VERSION ""

NS_ :

BS_:

BU_:

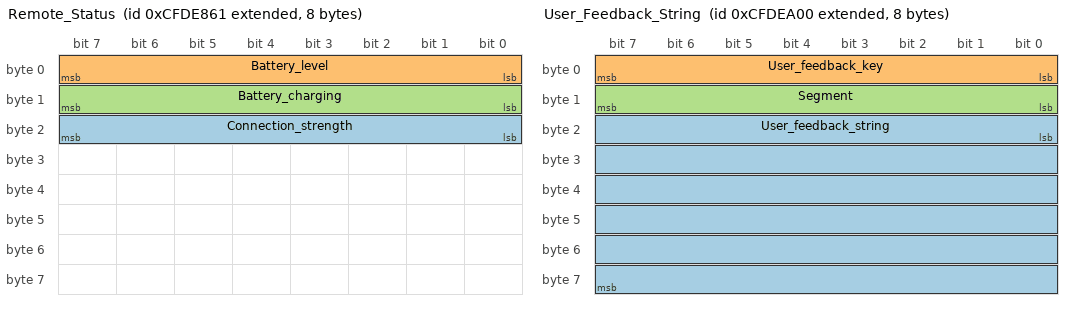
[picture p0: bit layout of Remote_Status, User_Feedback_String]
BO_ 2365450337 Remote_Status: 8 Vector__XXX
 SG_ Connection_strength : 16|8@1+ (1,0) [0|0] "" Vector__XXX
 SG_ Battery_level : 0|8@1+ (1,0) [0|100] "" Vector__XXX
 SG_ Battery_charging : 8|8@1+ (1,0) [0|1] "" Vector__XXX

BO_ 2365450752 User_Feedback_String: 8 Vector__XXX
 SG_ User_feedback_string : 16|48@1+ (1,0) [0|0] "" Vector__XXX
 SG_ User_feedback_key : 0|8@1+ (1,0) [0|100] "" Vector__XXX
 SG_ Segment : 8|8@1+ (1,0) [0|2] "" Vector__XXX

BO_ 2365450496 User_Feedback_Val: 8 Vector__XXX
 SG_ User_feedback_value : 8|32@1+ (1,0) [0|0] "" Vector__XXX
 SG_ User_feedback_key : 0|8@1+ (1,0) [0|100] "" Vector__XXX

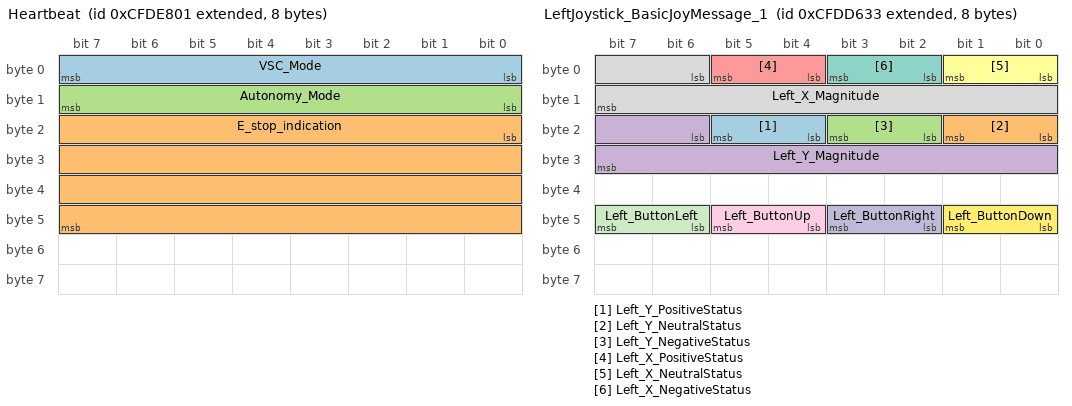
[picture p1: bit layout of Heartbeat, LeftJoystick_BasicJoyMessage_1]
BO_ 2365450241 Heartbeat: 8 Vector__XXX
 SG_ VSC_Mode : 0|8@1+ (1,0) [0|255] "" Vector__XXX
 SG_ E_stop_indication : 16|32@1+ (1,0) [0|4294967295] "" Vector__XXX
 SG_ Autonomy_Mode : 8|8@1+ (1,0) [0|255] "" Vector__XXX

BO_ 2365445683 LeftJoystick_BasicJoyMessage_1: 8 Vector__XXX
 SG_ Left_Y_PositiveStatus : 20|2@1+ (1,0) [0|3] "" Vector__XXX
 SG_ Left_Y_NeutralStatus : 16|2@1+ (1,0) [0|3] "" Vector__XXX
 SG_ Left_Y_NegativeStatus : 18|2@1+ (1,0) [0|3] "" Vector__XXX
 SG_ Left_Y_Magnitude : 22|10@1+ (1,0) [0|1] "" Vector__XXX
 SG_ Left_X_PositiveStatus : 4|2@1+ (1,0) [0|3] "" Vector__XXX
 SG_ Left_X_NeutralStatus : 0|2@1+ (1,0) [0|3] "" Vector__XXX
 SG_ Left_X_NegativeStatus : 2|2@1+ (1,0) [0|3] "" Vector__XXX
 SG_ Left_X_Magnitude : 6|10@1+ (1,0) [0|1] "" Vector__XXX
 SG_ Left_ButtonUp : 44|2@1+ (1,0) [0|3] "" Vector__XXX
 SG_ Left_ButtonRight : 42|2@1+ (1,0) [0|3] "" Vector__XXX
 SG_ Left_ButtonLeft : 46|2@1+ (1,0) [0|3] "" Vector__XXX
 SG_ Left_ButtonDown : 40|2@1+ (1,0) [0|3] "" Vector__XXX

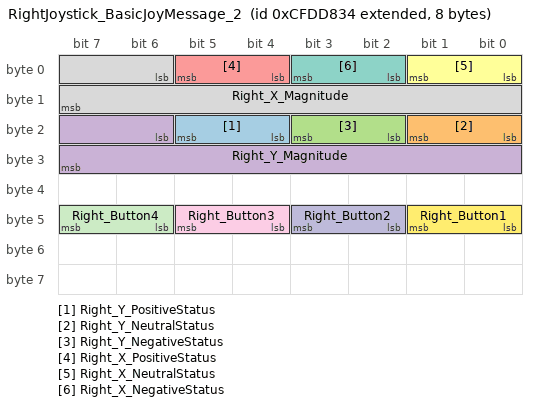
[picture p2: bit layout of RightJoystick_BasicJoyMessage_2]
BO_ 2365446196 RightJoystick_BasicJoyMessage_2: 8 Vector__XXX
 SG_ Right_Y_PositiveStatus : 20|2@1+ (1,0) [0|3] "" Vector__XXX
 SG_ Right_Y_NeutralStatus : 16|2@1+ (1,0) [0|3] "" Vector__XXX
 SG_ Right_Y_NegativeStatus : 18|2@1+ (1,0) [0|3] "" Vector__XXX
 SG_ Right_Y_Magnitude : 22|10@1+ (1,0) [0|1] "" Vector__XXX
 SG_ Right_X_PositiveStatus : 4|2@1+ (1,0) [0|3] "" Vector__XXX
 SG_ Right_X_NeutralStatus : 0|2@1+ (1,0) [0|3] "" Vector__XXX
 SG_ Right_X_NegativeStatus : 2|2@1+ (1,0) [0|3] "" Vector__XXX
 SG_ Right_X_Magnitude : 6|10@1+ (1,0) [0|1] "" Vector__XXX
 SG_ Right_Button3 : 44|2@1+ (1,0) [0|3] "" Vector__XXX
 SG_ Right_Button2 : 42|2@1+ (1,0) [0|3] "" Vector__XXX
 SG_ Right_Button4 : 46|2@1+ (1,0) [0|3] "" Vector__XXX
 SG_ Right_Button1 : 40|2@1+ (1,0) [0|3] "" Vector__XXX

BA_DEF_ SG_  "SigType" ENUM  "Default","Range","RangeSigned","ASCII","Discrete","Control","ReferencePGN","DTC","StringDelimiter","StringLength","StringLengthControl","MessageCounter","MessageChecksum";
BA_DEF_ SG_  "GenSigEVName" STRING ;
BA_DEF_ SG_  "GenSigILSupport" ENUM  "No","Yes";
BA_DEF_ SG_  "GenSigSendType" ENUM  "Cyclic","OnWrite","OnWriteWithRepetition","OnChange","OnChangeWithRepetition","IfActive","IfActiveWithRepetition","NoSigSendType";
BA_DEF_ BO_  "GenMsgILSupport" ENUM  "No","Yes";
BA_DEF_ BU_  "NmStationAddress" INT 0 255;
BA_DEF_ BO_  "GenMsgSendType" ENUM  "cyclic","NotUsed","IfActive","NotUsed","NotUsed","NotUsed","NotUsed","NotUsed","noMsgSendType";
BA_DEF_ BO_  "GenMsgRequestable" INT 0 1;
BA_DEF_  "DBName" STRING ;
BA_DEF_  "BusType" STRING ;
BA_DEF_  "ProtocolType" STRING ;
BA_DEF_ BO_  "VFrameFormat" ENUM  "StandardCAN","ExtendedCAN","reserved","J1939PG";
BA_DEF_DEF_  "SigType" "Default";
BA_DEF_DEF_  "GenSigEVName" "Env@Nodename_@Signame";
BA_DEF_DEF_  "GenSigILSupport" "Yes";
BA_DEF_DEF_  "GenSigSendType" "NoSigSendType";
BA_DEF_DEF_  "GenMsgILSupport" "Yes";
BA_DEF_DEF_  "NmStationAddress" 254;
BA_DEF_DEF_  "GenMsgSendType" "noMsgSendType";
BA_DEF_DEF_  "GenMsgRequestable" 1;
BA_DEF_DEF_  "DBName" "";
BA_DEF_DEF_  "BusType" "CAN";
BA_DEF_DEF_  "ProtocolType" "J1939";
BA_DEF_DEF_  "VFrameFormat" "J1939PG";
BA_ "DBName" "do13_fort";
